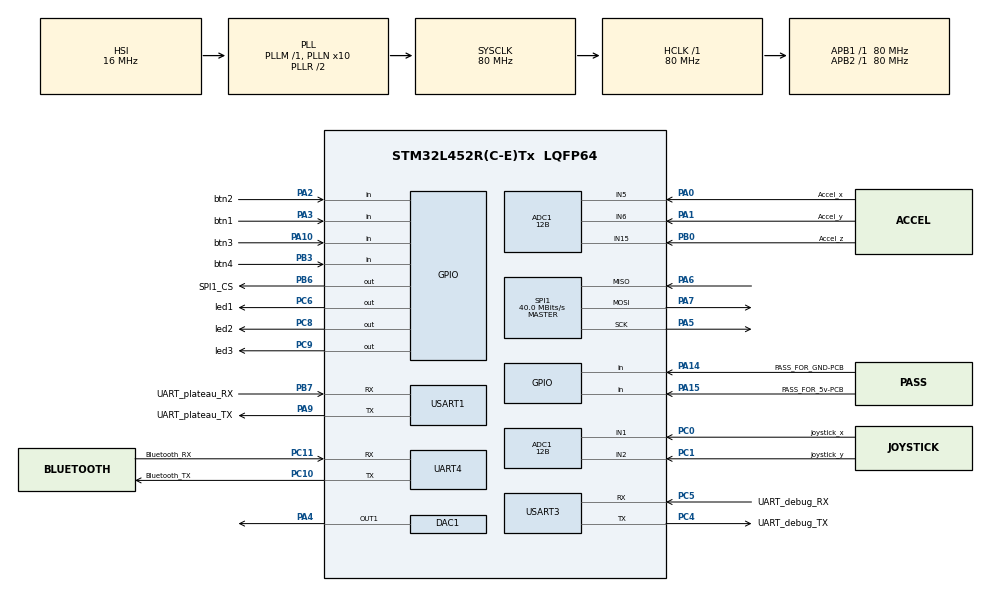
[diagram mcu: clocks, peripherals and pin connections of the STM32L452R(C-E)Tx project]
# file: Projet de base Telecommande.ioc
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ADC1.Channel-0\#ChannelRegularConversion=ADC_CHANNEL_1
ADC1.Channel-3\#ChannelRegularConversion=ADC_CHANNEL_2
ADC1.Channel-4\#ChannelRegularConversion=ADC_CHANNEL_5
ADC1.Channel-5\#ChannelRegularConversion=ADC_CHANNEL_6
ADC1.Channel-6\#ChannelRegularConversion=ADC_CHANNEL_15
ADC1.ClockPrescaler=ADC_CLOCK_ASYNC_DIV1
ADC1.ContinuousConvMode=DISABLE
ADC1.DMAContinuousRequests=DISABLE
ADC1.DataAlign=ADC_DATAALIGN_RIGHT
ADC1.DiscontinuousConvMode=DISABLE
ADC1.EOCSelection=ADC_EOC_SINGLE_CONV
ADC1.EnableAnalogWatchDog1=false
ADC1.EnableAnalogWatchDog2=false
ADC1.EnableAnalogWatchDog3=false
ADC1.EnableInjectedConversion=DISABLE
ADC1.EnableRegularConversion=ENABLE
ADC1.ExternalTrigConv=ADC_SOFTWARE_START
ADC1.ExternalTrigConvEdge=ADC_EXTERNALTRIGCONVEDGE_NONE
ADC1.LowPowerAutoWait=DISABLE
ADC1.NbrOfConversion=5
ADC1.NbrOfConversionFlag=1
ADC1.OffsetNumber-0\#ChannelRegularConversion=ADC_OFFSET_NONE
ADC1.OffsetNumber-3\#ChannelRegularConversion=ADC_OFFSET_NONE
ADC1.OffsetNumber-4\#ChannelRegularConversion=ADC_OFFSET_NONE
ADC1.OffsetNumber-5\#ChannelRegularConversion=ADC_OFFSET_NONE
ADC1.OffsetNumber-6\#ChannelRegularConversion=ADC_OFFSET_NONE
ADC1.Overrun=ADC_OVR_DATA_PRESERVED
ADC1.OversamplingMode=DISABLE
ADC1.Rank-0\#ChannelRegularConversion=1
ADC1.Rank-3\#ChannelRegularConversion=2
ADC1.Rank-4\#ChannelRegularConversion=3
ADC1.Rank-5\#ChannelRegularConversion=4
ADC1.Rank-6\#ChannelRegularConversion=5
ADC1.Resolution=ADC_RESOLUTION_12B
ADC1.SamplingTime-0\#ChannelRegularConversion=ADC_SAMPLETIME_2CYCLES_5
ADC1.SamplingTime-3\#ChannelRegularConversion=ADC_SAMPLETIME_2CYCLES_5
ADC1.SamplingTime-4\#ChannelRegularConversion=ADC_SAMPLETIME_2CYCLES_5
ADC1.SamplingTime-5\#ChannelRegularConversion=ADC_SAMPLETIME_2CYCLES_5
ADC1.SamplingTime-6\#ChannelRegularConversion=ADC_SAMPLETIME_2CYCLES_5
ADC1.ScanConvMode=ADC_SCAN_ENABLE
ADC1.master=1
Mcu.Family=STM32L4
Mcu.Name=STM32L452R(C-E)Tx
Mcu.Package=LQFP64
NVIC.ADC1_IRQn=true\:0\:0\:false\:false\:true\:true
NVIC.PriorityGroup=NVIC_PRIORITYGROUP_4
PA0.GPIO_Label=Accel_x
PA0.GPIO_Mode=GPIO_MODE_ANALOG_ADC_CONTROL
PA0.GPIO_PuPd=GPIO_NOPULL
PA0.Signal=ADCx_IN5
PA1.GPIO_Label=Accel_y
PA1.GPIO_Mode=GPIO_MODE_ANALOG_ADC_CONTROL
PA1.GPIO_PuPd=GPIO_NOPULL
PA1.Signal=ADCx_IN6
PA10.GPIO_Label=btn3
PA10.GPIO_Mode=GPIO_MODE_INPUT
PA10.GPIO_PuPd=GPIO_NOPULL
PA10.Signal=GPIO_Input
PA14\ (JTCK/SWCLK).GPIO_Label=PASS_FOR_GND-PCB
PA14\ (JTCK/SWCLK).Signal=GPIO_Input
PA15\ (JTDI).GPIO_Label=PASS_FOR_5v-PCB
PA15\ (JTDI).Signal=GPIO_Input
PA2.GPIO_Label=btn2
PA2.GPIO_Mode=GPIO_MODE_INPUT
PA2.GPIO_PuPd=GPIO_NOPULL
PA2.Signal=GPIO_Input
PA3.GPIO_Label=btn1
PA3.GPIO_Mode=GPIO_MODE_INPUT
PA3.GPIO_PuPd=GPIO_NOPULL
PA3.Signal=GPIO_Input
PA4.GPIO_Mode=GPIO_MODE_ANALOG
PA4.GPIO_PuPd=GPIO_NOPULL
PA4.Signal=COMP_DAC11_group
PA5.Mode=Full_Duplex_Master
PA5.Signal=SPI1_SCK
PA6.Mode=Full_Duplex_Master
PA6.Signal=SPI1_MISO
PA7.Mode=Full_Duplex_Master
PA7.Signal=SPI1_MOSI
PA9.GPIO_Label=UART_plateau_TX
PA9.GPIO_ModeDefaultPP=GPIO_MODE_AF_PP
PA9.GPIO_PuPd=GPIO_NOPULL
PA9.GPIO_Speed=GPIO_SPEED_FREQ_VERY_HIGH
PA9.Mode=Asynchronous
PA9.Signal=USART1_TX
PB0.GPIO_Label=Accel_z
PB0.GPIO_Mode=GPIO_MODE_ANALOG_ADC_CONTROL
PB0.GPIO_PuPd=GPIO_NOPULL
PB0.Signal=ADCx_IN15
PB3\ (JTDO/TRACESWO).GPIO_Label=btn4
PB3\ (JTDO/TRACESWO).GPIO_Mode=GPIO_MODE_INPUT
PB3\ (JTDO/TRACESWO).GPIO_PuPd=GPIO_NOPULL
PB3\ (JTDO/TRACESWO).Signal=GPIO_Input
PB6.GPIO_Label=SPI1_CS
PB6.Signal=GPIO_Output
PB7.GPIO_FM7=__NULL
PB7.GPIO_Label=UART_plateau_RX
PB7.GPIO_ModeDefaultPP=GPIO_MODE_AF_PP
PB7.GPIO_PuPd=GPIO_NOPULL
PB7.GPIO_Speed=GPIO_SPEED_FREQ_VERY_HIGH
PB7.Mode=Asynchronous
PB7.Signal=USART1_RX
PC0.GPIO_Label=joystick_x
PC0.GPIO_Mode=GPIO_MODE_ANALOG_ADC_CONTROL
PC0.GPIO_PuPd=GPIO_NOPULL
PC0.Signal=ADCx_IN1
PC1.GPIO_Label=joystick_y
PC1.GPIO_Mode=GPIO_MODE_ANALOG_ADC_CONTROL
PC1.GPIO_PuPd=GPIO_NOPULL
PC1.Signal=ADCx_IN2
PC10.GPIO_Label=Bluetooth_TX
PC10.GPIO_ModeDefaultPP=GPIO_MODE_AF_PP
PC10.GPIO_PuPd=GPIO_NOPULL
PC10.GPIO_Speed=GPIO_SPEED_FREQ_VERY_HIGH
PC10.Mode=Asynchronous
PC10.Signal=UART4_TX
PC11.GPIO_Label=Bluetooth_RX
PC11.GPIO_ModeDefaultPP=GPIO_MODE_AF_PP
PC11.GPIO_PuPd=GPIO_NOPULL
PC11.GPIO_Speed=GPIO_SPEED_FREQ_VERY_HIGH
PC11.Mode=Asynchronous
PC11.Signal=UART4_RX
PC4.GPIO_Label=UART_debug_TX
PC4.GPIO_ModeDefaultPP=GPIO_MODE_AF_PP
PC4.GPIO_PuPd=GPIO_NOPULL
PC4.GPIO_Speed=GPIO_SPEED_FREQ_VERY_HIGH
PC4.Mode=Asynchronous
PC4.Signal=USART3_TX
PC5.GPIO_Label=UART_debug_RX
PC5.GPIO_ModeDefaultPP=GPIO_MODE_AF_PP
PC5.GPIO_PuPd=GPIO_NOPULL
PC5.GPIO_Speed=GPIO_SPEED_FREQ_VERY_HIGH
PC5.Mode=Asynchronous
PC5.Signal=USART3_RX
PC6.GPIO_Label=led1
PC6.GPIO_ModeDefaultOutputPP=GPIO_MODE_OUTPUT_PP
PC6.GPIO_PuPd=GPIO_NOPULL
PC6.GPIO_Speed=GPIO_SPEED_FREQ_LOW
PC6.PinState=GPIO_PIN_RESET
PC6.Signal=GPIO_Output
PC8.GPIO_Label=led2
PC8.GPIO_ModeDefaultOutputPP=GPIO_MODE_OUTPUT_PP
PC8.GPIO_PuPd=GPIO_NOPULL
PC8.GPIO_Speed=GPIO_SPEED_FREQ_LOW
PC8.PinState=GPIO_PIN_RESET
PC8.Signal=GPIO_Output
PC9.GPIO_Label=led3
PC9.GPIO_ModeDefaultOutputPP=GPIO_MODE_OUTPUT_PP
PC9.GPIO_PuPd=GPIO_NOPULL
PC9.GPIO_Speed=GPIO_SPEED_FREQ_LOW
PC9.PinState=GPIO_PIN_RESET
PC9.Signal=GPIO_Output
ProjectManager.HeapSize=0x200
ProjectManager.StackSize=0x400
ProjectManager.TargetToolchain=SW4STM32
RCC.ADCFreq_Value=64000000
RCC.AHBFreq_Value=80000000
RCC.APB1Freq_Value=80000000
RCC.APB1TimFreq_Value=80000000
RCC.APB2Freq_Value=80000000
RCC.APB2TimFreq_Value=80000000
RCC.CortexFreq_Value=80000000
RCC.HCLKFreq_Value=80000000
RCC.HSE_VALUE=8000000
RCC.HSI48_VALUE=48000000
RCC.HSI_VALUE=16000000
RCC.LSE_VALUE=32768
RCC.MSI_VALUE=4000000
RCC.PLLN=10
RCC.PLLSourceVirtual=RCC_PLLSOURCE_HSI
RCC.PREFETCH_ENABLE=1
RCC.SYSCLKFreq_VALUE=80000000
RCC.SYSCLKSource=RCC_SYSCLKSOURCE_PLLCLK
RCC.USBFreq_Value=64000000
RCC.VCOOutputFreq_Value=160000000
SH.ADCx_IN1.0=ADC1_IN1,IN1-Single-Ended
SH.ADCx_IN15.0=ADC1_IN15,IN15-Single-Ended
SH.ADCx_IN2.0=ADC1_IN2,IN2-Single-Ended
SH.ADCx_IN5.0=ADC1_IN5,IN5-Single-Ended
SH.ADCx_IN6.0=ADC1_IN6,IN6-Single-Ended
SH.COMP_DAC11_group.0=DAC1_OUT1,DAC_OUT1
SPI1.CalculateBaudRate=40.0 MBits/s
SPI1.Direction=SPI_DIRECTION_2LINES
SPI1.Mode=SPI_MODE_MASTER
SPI1.VirtualType=VM_MASTER
USART1.VirtualMode-Asynchronous=VM_ASYNC
USART3.VirtualMode-Asynchronous=VM_ASYNC
board=NUCLEO-L452RE

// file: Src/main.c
/**
  ******************************************************************************
  * @file           : main.c
  * @brief          : Main program body
  ******************************************************************************
  ** This notice applies to any and all portions of this file
  * that are not between comment pairs USER CODE BEGIN and
  * USER CODE END. Other portions of this file, whether
  * inserted by the user or by software development tools
  * are owned by their respective copyright owners.
  *
  * COPYRIGHT(c) 2019 STMicroelectronics
  *
  * Redistribution and use in source and binary forms, with or without modification,
  * are permitted provided that the following conditions are met:
  *   1. Redistributions of source code must retain the above copyright notice,
  *      this list of conditions and the following disclaimer.
  *   2. Redistributions in binary form must reproduce the above copyright notice,
  *      this list of conditions and the following disclaimer in the documentation
  *      and/or other materials provided with the distribution.
  *   3. Neither the name of STMicroelectronics nor the names of its contributors
  *      may be used to endorse or promote products derived from this software
  *      without specific prior written permission.
  *
  * THIS SOFTWARE IS PROVIDED BY THE COPYRIGHT HOLDERS AND CONTRIBUTORS "AS IS"
  * AND ANY EXPRESS OR IMPLIED WARRANTIES, INCLUDING, BUT NOT LIMITED TO, THE
  * IMPLIED WARRANTIES OF MERCHANTABILITY AND FITNESS FOR A PARTICULAR PURPOSE ARE
  * DISCLAIMED. IN NO EVENT SHALL THE COPYRIGHT HOLDER OR CONTRIBUTORS BE LIABLE
  * FOR ANY DIRECT, INDIRECT, INCIDENTAL, SPECIAL, EXEMPLARY, OR CONSEQUENTIAL
  * DAMAGES (INCLUDING, BUT NOT LIMITED TO, PROCUREMENT OF SUBSTITUTE GOODS OR
  * SERVICES; LOSS OF USE, DATA, OR PROFITS; OR BUSINESS INTERRUPTION) HOWEVER
  * CAUSED AND ON ANY THEORY OF LIABILITY, WHETHER IN CONTRACT, STRICT LIABILITY,
  * OR TORT (INCLUDING NEGLIGENCE OR OTHERWISE) ARISING IN ANY WAY OUT OF THE USE
  * OF THIS SOFTWARE, EVEN IF ADVISED OF THE POSSIBILITY OF SUCH DAMAGE.
  *
  ******************************************************************************
  */
#include "main.h"
#include "stm32l4xx_hal.h"

ADC_HandleTypeDef hadc1;

DAC_HandleTypeDef hdac1;

SPI_HandleTypeDef hspi1;

UART_HandleTypeDef huart4;
UART_HandleTypeDef huart1;
UART_HandleTypeDef huart3;

/* USER CODE BEGIN PV */
/* Private variables ---------------------------------------------------------*/
uint32_t ADC_BUF[5];

/* USER CODE END PV */

void SystemClock_Config(void);
static void MX_GPIO_Init(void);
static void MX_ADC1_Init(void);
static void MX_DAC1_Init(void);
static void MX_UART4_Init(void);
static void MX_USART1_UART_Init(void);
static void MX_USART3_UART_Init(void);
static void MX_SPI1_Init(void);

/* USER CODE BEGIN PFP */
/* Private function prototypes -----------------------------------------------*/

/* USER CODE END PFP */

/* USER CODE BEGIN 0 */
void HAL_ADC_ConvCpltCallback(ADC_HandleTypeDef* hadc){
	uint32_t valADC[5];
	if(hadc->Instance == ADC1){
		valADC[0] = ADC_BUF[0];
		valADC[1] = ADC_BUF[1];
		valADC[2] = ADC_BUF[2];
		valADC[3] = ADC_BUF[3];
		valADC[4] = ADC_BUF[4];
	}
}
/* USER CODE END 0 */

int main(void)
{

  /* MCU Configuration----------------------------------------------------------*/

  /* Reset of all peripherals, Initializes the Flash interface and the Systick. */
  HAL_Init();

  /* Configure the system clock */
  SystemClock_Config();

  /* Initialize all configured peripherals */
  MX_GPIO_Init();
  MX_ADC1_Init();
  MX_DAC1_Init();
  MX_UART4_Init();
  MX_USART1_UART_Init();
  MX_USART3_UART_Init();
  MX_SPI1_Init();
  /* USER CODE BEGIN 2 */
  HAL_ADC_Start_DMA(&hadc1,(uint32_t*)ADC_BUF, 5);
  HAL_ADC_Start_IT(&hadc1);
  /* USER CODE END 2 */

  /* Infinite loop */
  /* USER CODE BEGIN WHILE */
  while (1)
  {
	  HAL_ADC_Start_IT(&hadc1);
	  HAL_Delay(100);
  /* USER CODE END WHILE */

  }

}

void SystemClock_Config(void)
{

  RCC_OscInitTypeDef RCC_OscInitStruct;
  RCC_ClkInitTypeDef RCC_ClkInitStruct;
  RCC_PeriphCLKInitTypeDef PeriphClkInit;

    /**Initializes the CPU, AHB and APB busses clocks
    */
  RCC_OscInitStruct.OscillatorType = RCC_OSCILLATORTYPE_HSI;
  RCC_OscInitStruct.HSIState = RCC_HSI_ON;
  RCC_OscInitStruct.HSICalibrationValue = 16;
  RCC_OscInitStruct.PLL.PLLState = RCC_PLL_ON;
  RCC_OscInitStruct.PLL.PLLSource = RCC_PLLSOURCE_HSI;
  RCC_OscInitStruct.PLL.PLLM = 1;
  RCC_OscInitStruct.PLL.PLLN = 10;
  RCC_OscInitStruct.PLL.PLLP = RCC_PLLP_DIV7;
  RCC_OscInitStruct.PLL.PLLQ = RCC_PLLQ_DIV2;
  RCC_OscInitStruct.PLL.PLLR = RCC_PLLR_DIV2;
  if (HAL_RCC_OscConfig(&RCC_OscInitStruct) != HAL_OK)
  {
    _Error_Handler(__FILE__, __LINE__);
  }

    /**Initializes the CPU, AHB and APB busses clocks
    */
  RCC_ClkInitStruct.ClockType = RCC_CLOCKTYPE_HCLK|RCC_CLOCKTYPE_SYSCLK
                              |RCC_CLOCKTYPE_PCLK1|RCC_CLOCKTYPE_PCLK2;
  RCC_ClkInitStruct.SYSCLKSource = RCC_SYSCLKSOURCE_PLLCLK;
  RCC_ClkInitStruct.AHBCLKDivider = RCC_SYSCLK_DIV1;
  RCC_ClkInitStruct.APB1CLKDivider = RCC_HCLK_DIV1;
  RCC_ClkInitStruct.APB2CLKDivider = RCC_HCLK_DIV1;

  if (HAL_RCC_ClockConfig(&RCC_ClkInitStruct, FLASH_LATENCY_4) != HAL_OK)
  {
    _Error_Handler(__FILE__, __LINE__);
  }

  PeriphClkInit.PeriphClockSelection = RCC_PERIPHCLK_USART1|RCC_PERIPHCLK_USART3
                              |RCC_PERIPHCLK_UART4|RCC_PERIPHCLK_ADC;
  PeriphClkInit.Usart1ClockSelection = RCC_USART1CLKSOURCE_PCLK2;
  PeriphClkInit.Usart3ClockSelection = RCC_USART3CLKSOURCE_PCLK1;
  PeriphClkInit.Uart4ClockSelection = RCC_UART4CLKSOURCE_PCLK1;
  PeriphClkInit.AdcClockSelection = RCC_ADCCLKSOURCE_PLLSAI1;
  PeriphClkInit.PLLSAI1.PLLSAI1Source = RCC_PLLSOURCE_HSI;
  PeriphClkInit.PLLSAI1.PLLSAI1M = 1;
  PeriphClkInit.PLLSAI1.PLLSAI1N = 8;
  PeriphClkInit.PLLSAI1.PLLSAI1P = RCC_PLLP_DIV7;
  PeriphClkInit.PLLSAI1.PLLSAI1Q = RCC_PLLQ_DIV2;
  PeriphClkInit.PLLSAI1.PLLSAI1R = RCC_PLLR_DIV2;
  PeriphClkInit.PLLSAI1.PLLSAI1ClockOut = RCC_PLLSAI1_ADC1CLK;
  if (HAL_RCCEx_PeriphCLKConfig(&PeriphClkInit) != HAL_OK)
  {
    _Error_Handler(__FILE__, __LINE__);
  }

    /**Configure the main internal regulator output voltage
    */
  if (HAL_PWREx_ControlVoltageScaling(PWR_REGULATOR_VOLTAGE_SCALE1) != HAL_OK)
  {
    _Error_Handler(__FILE__, __LINE__);
  }

    /**Configure the Systick interrupt time
    */
  HAL_SYSTICK_Config(HAL_RCC_GetHCLKFreq()/1000);

    /**Configure the Systick
    */
  HAL_SYSTICK_CLKSourceConfig(SYSTICK_CLKSOURCE_HCLK);

  /* SysTick_IRQn interrupt configuration */
  HAL_NVIC_SetPriority(SysTick_IRQn, 0, 0);
}

/* ADC1 init function */
static void MX_ADC1_Init(void)
{

  ADC_ChannelConfTypeDef sConfig;

    /**Common config
    */
  hadc1.Instance = ADC1;
  hadc1.Init.ClockPrescaler = ADC_CLOCK_ASYNC_DIV1;
  hadc1.Init.Resolution = ADC_RESOLUTION_12B;
  hadc1.Init.DataAlign = ADC_DATAALIGN_RIGHT;
  hadc1.Init.ScanConvMode = ADC_SCAN_ENABLE;
  hadc1.Init.EOCSelection = ADC_EOC_SINGLE_CONV;
  hadc1.Init.LowPowerAutoWait = DISABLE;
  hadc1.Init.ContinuousConvMode = DISABLE;
  hadc1.Init.NbrOfConversion = 5;
  hadc1.Init.DiscontinuousConvMode = DISABLE;
  hadc1.Init.ExternalTrigConv = ADC_SOFTWARE_START;
  hadc1.Init.ExternalTrigConvEdge = ADC_EXTERNALTRIGCONVEDGE_NONE;
  hadc1.Init.DMAContinuousRequests = DISABLE;
  hadc1.Init.Overrun = ADC_OVR_DATA_PRESERVED;
  hadc1.Init.OversamplingMode = DISABLE;
  if (HAL_ADC_Init(&hadc1) != HAL_OK)
  {
    _Error_Handler(__FILE__, __LINE__);
  }

    /**Configure Regular Channel
    */
  sConfig.Channel = ADC_CHANNEL_2;
  sConfig.Rank = ADC_REGULAR_RANK_2;
  sConfig.SamplingTime = ADC_SAMPLETIME_2CYCLES_5;
  sConfig.SingleDiff = ADC_SINGLE_ENDED;
  sConfig.OffsetNumber = ADC_OFFSET_NONE;
  sConfig.Offset = 0;
  if (HAL_ADC_ConfigChannel(&hadc1, &sConfig) != HAL_OK)
  {
    _Error_Handler(__FILE__, __LINE__);
  }

    /**Configure Regular Channel
    */
  sConfig.Channel = ADC_CHANNEL_5;
  sConfig.Rank = ADC_REGULAR_RANK_3;
  if (HAL_ADC_ConfigChannel(&hadc1, &sConfig) != HAL_OK)
  {
    _Error_Handler(__FILE__, __LINE__);
  }

    /**Configure Regular Channel
    */
  sConfig.Channel = ADC_CHANNEL_6;
  sConfig.Rank = ADC_REGULAR_RANK_4;
  if (HAL_ADC_ConfigChannel(&hadc1, &sConfig) != HAL_OK)
  {
    _Error_Handler(__FILE__, __LINE__);
  }

    /**Configure Regular Channel
    */
  sConfig.Channel = ADC_CHANNEL_15;
  sConfig.Rank = ADC_REGULAR_RANK_5;
  if (HAL_ADC_ConfigChannel(&hadc1, &sConfig) != HAL_OK)
  {
    _Error_Handler(__FILE__, __LINE__);
  }

    /**Configure Regular Channel
    */
  sConfig.Channel = ADC_CHANNEL_1;
  sConfig.Rank = ADC_REGULAR_RANK_1;
  if (HAL_ADC_ConfigChannel(&hadc1, &sConfig) != HAL_OK)
  {
    _Error_Handler(__FILE__, __LINE__);
  }

}

/* DAC1 init function */
static void MX_DAC1_Init(void)
{

  DAC_ChannelConfTypeDef sConfig;

    /**DAC Initialization
    */
  hdac1.Instance = DAC1;
  if (HAL_DAC_Init(&hdac1) != HAL_OK)
  {
    _Error_Handler(__FILE__, __LINE__);
  }

    /**DAC channel OUT1 config
    */
  sConfig.DAC_SampleAndHold = DAC_SAMPLEANDHOLD_DISABLE;
  sConfig.DAC_Trigger = DAC_TRIGGER_NONE;
  sConfig.DAC_OutputBuffer = DAC_OUTPUTBUFFER_ENABLE;
  sConfig.DAC_ConnectOnChipPeripheral = DAC_CHIPCONNECT_DISABLE;
  sConfig.DAC_UserTrimming = DAC_TRIMMING_FACTORY;
  if (HAL_DAC_ConfigChannel(&hdac1, &sConfig, DAC_CHANNEL_1) != HAL_OK)
  {
    _Error_Handler(__FILE__, __LINE__);
  }

}

/* SPI1 init function */
static void MX_SPI1_Init(void)
{

  /* SPI1 parameter configuration*/
  hspi1.Instance = SPI1;
  hspi1.Init.Mode = SPI_MODE_MASTER;
  hspi1.Init.Direction = SPI_DIRECTION_2LINES;
  hspi1.Init.DataSize = SPI_DATASIZE_4BIT;
  hspi1.Init.CLKPolarity = SPI_POLARITY_LOW;
  hspi1.Init.CLKPhase = SPI_PHASE_1EDGE;
  hspi1.Init.NSS = SPI_NSS_SOFT;
  hspi1.Init.BaudRatePrescaler = SPI_BAUDRATEPRESCALER_2;
  hspi1.Init.FirstBit = SPI_FIRSTBIT_MSB;
  hspi1.Init.TIMode = SPI_TIMODE_DISABLE;
  hspi1.Init.CRCCalculation = SPI_CRCCALCULATION_DISABLE;
  hspi1.Init.CRCPolynomial = 7;
  hspi1.Init.CRCLength = SPI_CRC_LENGTH_DATASIZE;
  hspi1.Init.NSSPMode = SPI_NSS_PULSE_ENABLE;
  if (HAL_SPI_Init(&hspi1) != HAL_OK)
  {
    _Error_Handler(__FILE__, __LINE__);
  }

}

/* UART4 init function */
static void MX_UART4_Init(void)
{

  huart4.Instance = UART4;
  huart4.Init.BaudRate = 115200;
  huart4.Init.WordLength = UART_WORDLENGTH_8B;
  huart4.Init.StopBits = UART_STOPBITS_1;
  huart4.Init.Parity = UART_PARITY_NONE;
  huart4.Init.Mode = UART_MODE_TX_RX;
  huart4.Init.HwFlowCtl = UART_HWCONTROL_NONE;
  huart4.Init.OverSampling = UART_OVERSAMPLING_16;
  huart4.Init.OneBitSampling = UART_ONE_BIT_SAMPLE_DISABLE;
  huart4.AdvancedInit.AdvFeatureInit = UART_ADVFEATURE_NO_INIT;
  if (HAL_UART_Init(&huart4) != HAL_OK)
  {
    _Error_Handler(__FILE__, __LINE__);
  }

}

/* USART1 init function */
static void MX_USART1_UART_Init(void)
{

  huart1.Instance = USART1;
  huart1.Init.BaudRate = 115200;
  huart1.Init.WordLength = UART_WORDLENGTH_8B;
  huart1.Init.StopBits = UART_STOPBITS_1;
  huart1.Init.Parity = UART_PARITY_NONE;
  huart1.Init.Mode = UART_MODE_TX_RX;
  huart1.Init.HwFlowCtl = UART_HWCONTROL_NONE;
  huart1.Init.OverSampling = UART_OVERSAMPLING_16;
  huart1.Init.OneBitSampling = UART_ONE_BIT_SAMPLE_DISABLE;
  huart1.AdvancedInit.AdvFeatureInit = UART_ADVFEATURE_NO_INIT;
  if (HAL_UART_Init(&huart1) != HAL_OK)
  {
    _Error_Handler(__FILE__, __LINE__);
  }

}

/* USART3 init function */
static void MX_USART3_UART_Init(void)
{

  huart3.Instance = USART3;
  huart3.Init.BaudRate = 115200;
  huart3.Init.WordLength = UART_WORDLENGTH_8B;
  huart3.Init.StopBits = UART_STOPBITS_1;
  huart3.Init.Parity = UART_PARITY_NONE;
  huart3.Init.Mode = UART_MODE_TX_RX;
  huart3.Init.HwFlowCtl = UART_HWCONTROL_NONE;
  huart3.Init.OverSampling = UART_OVERSAMPLING_16;
  huart3.Init.OneBitSampling = UART_ONE_BIT_SAMPLE_DISABLE;
  huart3.AdvancedInit.AdvFeatureInit = UART_ADVFEATURE_NO_INIT;
  if (HAL_UART_Init(&huart3) != HAL_OK)
  {
    _Error_Handler(__FILE__, __LINE__);
  }

}

/** Configure pins as
        * Analog
        * Input
        * Output
        * EVENT_OUT
        * EXTI
*/
static void MX_GPIO_Init(void)
{

  GPIO_InitTypeDef GPIO_InitStruct;

  /* GPIO Ports Clock Enable */
  __HAL_RCC_GPIOC_CLK_ENABLE();
  __HAL_RCC_GPIOA_CLK_ENABLE();
  __HAL_RCC_GPIOB_CLK_ENABLE();

  /*Configure GPIO pin Output Level */
  HAL_GPIO_WritePin(GPIOC, led1_Pin|led2_Pin|led3_Pin, GPIO_PIN_RESET);

  /*Configure GPIO pin Output Level */
  HAL_GPIO_WritePin(SPI1_CS_GPIO_Port, SPI1_CS_Pin, GPIO_PIN_RESET);

  /*Configure GPIO pins : btn2_Pin btn1_Pin btn3_Pin PASS_FOR_GND_PCB_Pin
                           PASS_FOR_5v_PCB_Pin */
  GPIO_InitStruct.Pin = btn2_Pin|btn1_Pin|btn3_Pin|PASS_FOR_GND_PCB_Pin
                          |PASS_FOR_5v_PCB_Pin;
  GPIO_InitStruct.Mode = GPIO_MODE_INPUT;
  GPIO_InitStruct.Pull = GPIO_NOPULL;
  HAL_GPIO_Init(GPIOA, &GPIO_InitStruct);

  /*Configure GPIO pins : led1_Pin led2_Pin led3_Pin */
  GPIO_InitStruct.Pin = led1_Pin|led2_Pin|led3_Pin;
  GPIO_InitStruct.Mode = GPIO_MODE_OUTPUT_PP;
  GPIO_InitStruct.Pull = GPIO_NOPULL;
  GPIO_InitStruct.Speed = GPIO_SPEED_FREQ_LOW;
  HAL_GPIO_Init(GPIOC, &GPIO_InitStruct);

  /*Configure GPIO pin : btn4_Pin */
  GPIO_InitStruct.Pin = btn4_Pin;
  GPIO_InitStruct.Mode = GPIO_MODE_INPUT;
  GPIO_InitStruct.Pull = GPIO_NOPULL;
  HAL_GPIO_Init(btn4_GPIO_Port, &GPIO_InitStruct);

  /*Configure GPIO pin : SPI1_CS_Pin */
  GPIO_InitStruct.Pin = SPI1_CS_Pin;
  GPIO_InitStruct.Mode = GPIO_MODE_OUTPUT_PP;
  GPIO_InitStruct.Pull = GPIO_NOPULL;
  GPIO_InitStruct.Speed = GPIO_SPEED_FREQ_LOW;
  HAL_GPIO_Init(SPI1_CS_GPIO_Port, &GPIO_InitStruct);

}

void _Error_Handler(char *file, int line)
{
  while(1)
  {
  }
}

/************************ (C) COPYRIGHT STMicroelectronics *****END OF FILE****/
